# ESP32-S31 register map
Vendor: ESPRESSIF SYSTEMS (SHANGHAI) CO., LTD.; Series: ESP32 S-Series; File version: 1
CPU: RV32IMAFC r0p0, little endian, no MPU, FPU, 0 interrupt priority bits
Address unit: 32 bits
Registers are 32-bit, read-write, reset 0x0 unless marked. A register's access mark holds for its fields unless they carry their own. Offsets are from the block's base; [hi:lo] are bit positions; {n}, {i} and the like mark numbered series.

## IO_MUX — Input/Output Multiplexer
Base 0x20582000
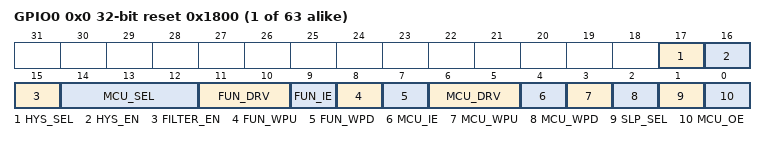
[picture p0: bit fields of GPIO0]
{0x0+4i} GPIO{i} (i=0..62) reset 0x1800 — IO MUX configuration register for GPIO{i}
  [17] HYS_SEL — Configures to choose the signal for enabling the hysteresis function for GPIO%s. \\ 0: Choose the output enable signal of eFuse\\ 1: Choose the output enable signal of IO_MUX_GPIO%s_HYS_EN\\
  [16] HYS_EN — Configures whether or not to enable the hysteresis function of the pin when IO_MUX_GPIO%s_HYS_SEL is set to 1.\\ 0: Disable\\ 1: Enable\\
  [15] FILTER_EN — Configures whether or not to enable filter for pin input signals.\\ 0: Disable\\ 1: Enable\\
  [14:12] MCU_SEL — Configures to select IO MUX function for this signal. \\ 0: Select Function 0\\ 1: Select Function 1\\ ......\\
  [11:10] FUN_DRV — Configures the drive strength of GPIO%s. \\ 0: ~5 mA\\ 1: ~10 mA\\ 2: ~20 mA\\ 3: ~40 mA\\
  [9] FUN_IE — Configures whether or not to enable input of GPIO%s.\\ 0: Disable\\ 1: Enable\\
  [8] FUN_WPU — Configures whether or not enable pull-up resistor of GPIO%s.\\ 0: Disable\\ 1: Enable\\
  [7] FUN_WPD — Configures whether or not to enable pull-down resistor of GPIO%s.\\ 0: Disable\\ 1: Enable\\
  [6:5] MCU_DRV — Configures the drive strength of GPIO%s during sleep mode. \\ 0: ~5 mA\\ 1: ~10 mA\\ 2: ~20 mA\\ 3: ~40 mA\\
  [4] MCU_IE — Configures whether or not to enable the input of GPIO%s during sleep mode.\\ 0: Disable\\ 1: Enable\\
  [3] MCU_WPU — Configures whether or not to enable pull-up resistor of GPIO%s during sleep mode. \\ 0: Disable\\ 1: Enable\\
  [2] MCU_WPD — Configure whether or not to enable pull-down resistor of GPIO%s in sleep mode.\\ 0: Disable\\ 1: Enable\\
  [1] SLP_SEL — Configures whether or not to enter sleep mode for GPIO%s.\\ 0: Not enter\\ 1: Enter\\
  [0] MCU_OE — Configures whether or not to enable the output of GPIO%s in sleep mode. 0: Disable\\ 1: Enable\\
0x1FC DATE reset 0x2502070 — Version control register
  [27:0] REG_DATE

## LP_ADI — LP_ADI Peripheral
Base 0x20805000
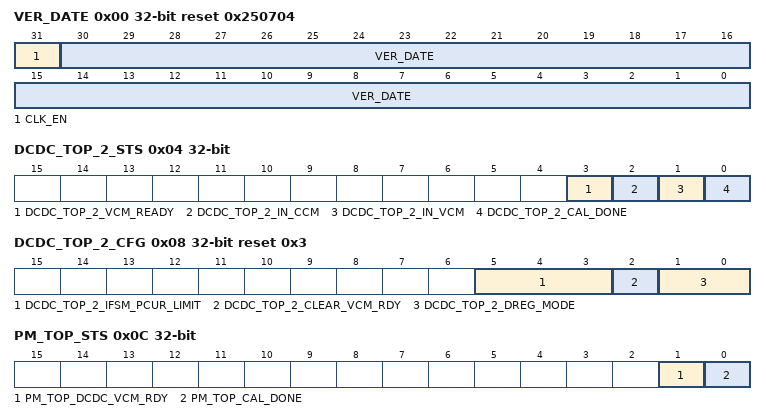
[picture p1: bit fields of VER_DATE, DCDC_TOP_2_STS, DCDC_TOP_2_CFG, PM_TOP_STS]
0x00 VER_DATE reset 0x250704 — need_des
  [31] CLK_EN — need_des
  [30:0] VER_DATE — need_des
0x04 DCDC_TOP_2_STS ro — ANALOG DCDC 2 related status
  [3] DCDC_TOP_2_VCM_READY — vcm_ready signal from dcdc 2 top
  [2] DCDC_TOP_2_IN_CCM — in ccm signal from dcdc 2 top
  [1] DCDC_TOP_2_IN_VCM — in vcm signal from dcdc 2 top
  [0] DCDC_TOP_2_CAL_DONE — cali done signal from dcdc 2 top
0x08 DCDC_TOP_2_CFG reset 0x3 — ANALOG DCDC 2 related CONFIG
  [5:3] DCDC_TOP_2_IFSM_PCUR_LIMIT — Current limit config
  [2] DCDC_TOP_2_CLEAR_VCM_RDY — 1: clear vcm rdy signal
  [1:0] DCDC_TOP_2_DREG_MODE — DCDC 2 dreg mode
0x0C PM_TOP_STS ro — ANALOG PM TOP related status
  [1] PM_TOP_DCDC_VCM_RDY — vcm_ready signal from PM TOP
  [0] PM_TOP_CAL_DONE — cali done signal from PM TOP
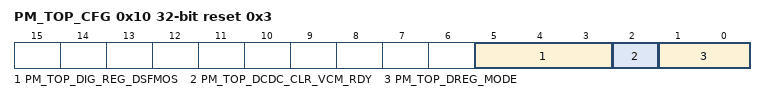
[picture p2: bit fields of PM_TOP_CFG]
0x10 PM_TOP_CFG reset 0x3 — ANALOG PM TOP related CONFIG
  [5:3] PM_TOP_DIG_REG_DSFMOS — Current limit config
  [2] PM_TOP_DCDC_CLR_VCM_RDY — 1: clear vcm rdy signal
  [1:0] PM_TOP_DREG_MODE

## LP_ANA_PERI — LP_ANA_PERI Peripheral
Base 0x20702000
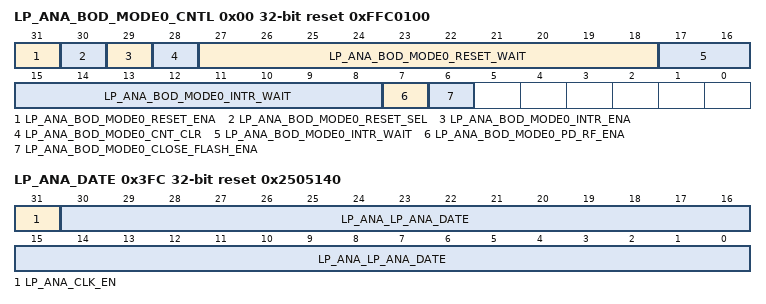
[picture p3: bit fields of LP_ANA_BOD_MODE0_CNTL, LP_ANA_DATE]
0x00 LP_ANA_BOD_MODE0_CNTL reset 0xFFC0100 — need_des
  [31] LP_ANA_BOD_MODE0_RESET_ENA — need_des
  [30] LP_ANA_BOD_MODE0_RESET_SEL — need_des
  [29] LP_ANA_BOD_MODE0_INTR_ENA — need_des
  [28] LP_ANA_BOD_MODE0_CNT_CLR — need_des
  [27:18] LP_ANA_BOD_MODE0_RESET_WAIT — need_des
  [17:8] LP_ANA_BOD_MODE0_INTR_WAIT — need_des
  [7] LP_ANA_BOD_MODE0_PD_RF_ENA — need_des
  [6] LP_ANA_BOD_MODE0_CLOSE_FLASH_ENA — need_des
0x04 LP_ANA_BOD_MODE1_CNTL — need_des
  [31] LP_ANA_BOD_MODE1_RESET_ENA
0x08 LP_ANA_VDD_SOURCE_CNTL reset 0x3F — need_des
  [5:0] LP_ANA_DETMODE_SEL
0x18 LP_ANA_PG_GLITCH_CNTL — need_des
  [31:26] LP_ANA_POWER_GLITCH_RESET_ENA
0x1C LP_ANA_FIB_ENABLE reset 0xFFFFFFFF — need_des
  [31:0] LP_ANA_ANA_FIB_ENA
0x20 LP_ANA_INT_RAW — need_des
  [31] LP_ANA_BOD_MODE0_INT_RAW
0x24 LP_ANA_INT_ST ro — need_des
  [31] LP_ANA_BOD_MODE0_INT_ST
0x28 LP_ANA_INT_ENA — need_des
  [31] LP_ANA_BOD_MODE0_INT_ENA
0x2C LP_ANA_INT_CLR wo — need_des
  [31] LP_ANA_BOD_MODE0_INT_CLR
0x30 LP_ANA_LP_INT_RAW — need_des
  [31] LP_ANA_BOD_MODE0_LP_INT_RAW
0x34 LP_ANA_LP_INT_ST ro — need_des
  [31] LP_ANA_BOD_MODE0_LP_INT_ST
0x38 LP_ANA_LP_INT_ENA — need_des
  [31] LP_ANA_BOD_MODE0_LP_INT_ENA
0x3C LP_ANA_LP_INT_CLR wo — need_des
  [31] LP_ANA_BOD_MODE0_LP_INT_CLR
0x3FC LP_ANA_DATE reset 0x2505140 — need_des
  [31] LP_ANA_CLK_EN — need_des
  [30:0] LP_ANA_LP_ANA_DATE — need_des
